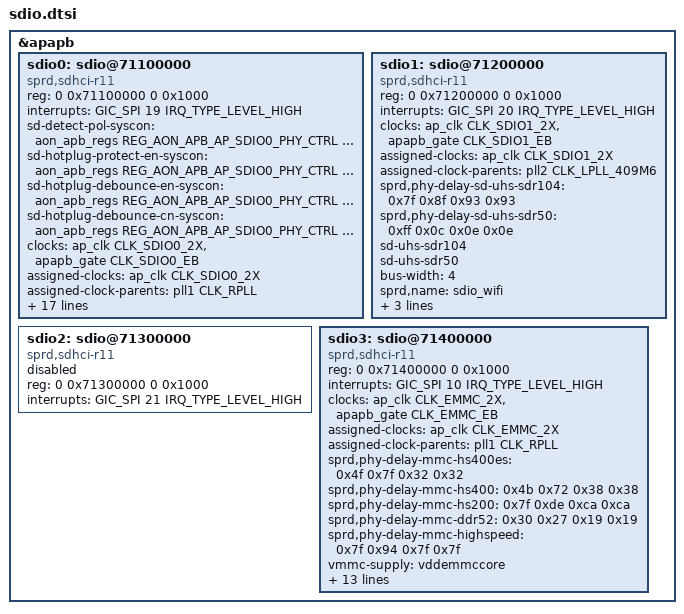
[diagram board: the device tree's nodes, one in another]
// SPDX-License-Identifier: GPL-2.0-only
/*
 * Unisoc UMS312 SDIO dts file
 *
 * Copyright (C) 2020~2021, Unisoc Communications Inc.
 */
&apapb {
	sdio0: sdio@71100000 {
		compatible = "sprd,sdhci-r11";
		reg = <0 0x71100000 0 0x1000>;
		interrupts = <GIC_SPI 19 IRQ_TYPE_LEVEL_HIGH>;
		sd-detect-pol-syscon = <&aon_apb_regs
			REG_AON_APB_AP_SDIO0_PHY_CTRL
			MASK_AON_APB_AP_SDIO0_CARD_PRESENT_32K>;
		sd-hotplug-protect-en-syscon = <&aon_apb_regs
			REG_AON_APB_AP_SDIO0_PHY_CTRL
			MASK_AON_APB_AP_SDIO0_CARD_PROTECT_32K>;
		sd-hotplug-debounce-en-syscon = <&aon_apb_regs
			REG_AON_APB_AP_SDIO0_PHY_CTRL
			MASK_AON_APB_AP_SDIO0_CARDDET_DBNC_EN_32K>;
		sd-hotplug-debounce-cn-syscon = <&aon_apb_regs
			REG_AON_APB_AP_SDIO0_PHY_CTRL
			MASK_AON_APB_AP_SDIO0_CARDDET_DBNC_THD_32K>;
		clock-names = "sdio","enable";
		clocks = <&ap_clk  CLK_SDIO0_2X>,
			<&apapb_gate CLK_SDIO0_EB>;
		assigned-clocks = <&ap_clk CLK_SDIO0_2X>;
		assigned-clock-parents = <&pll1 CLK_RPLL>;
		status = "disabled";
	};

	sdio1: sdio@71200000 {
		compatible = "sprd,sdhci-r11";
		reg = <0 0x71200000 0 0x1000>;
		interrupts = <GIC_SPI 20 IRQ_TYPE_LEVEL_HIGH>;
		clock-names = "sdio", "enable";
		clocks = <&ap_clk CLK_SDIO1_2X>,
			<&apapb_gate CLK_SDIO1_EB>;
		assigned-clocks = <&ap_clk CLK_SDIO1_2X>;
		assigned-clock-parents = <&pll2 CLK_LPLL_409M6>;
		status = "disabled";
	};

	sdio2: sdio@71300000 {
		compatible = "sprd,sdhci-r11";
		reg = <0 0x71300000 0 0x1000>;
		interrupts = <GIC_SPI 21 IRQ_TYPE_LEVEL_HIGH>;
		status = "disabled";
	};

	sdio3: sdio@71400000 {
		compatible = "sprd,sdhci-r11";
		reg = <0 0x71400000 0 0x1000>;
		interrupts = <GIC_SPI 10 IRQ_TYPE_LEVEL_HIGH>;
		clock-names = "sdio","enable";
		clocks = <&ap_clk CLK_EMMC_2X>,
			<&apapb_gate CLK_EMMC_EB>;
		assigned-clocks = <&ap_clk CLK_EMMC_2X>;
		assigned-clock-parents = <&pll1 CLK_RPLL>;
		status = "disabled";
	};
};

&sdio0 {
	sprd,phy-delay-sd-uhs-sdr104 = <0x86 0x6e 0x70 0x70>;
	sprd,phy-delay-sd-uhs-sdr50 = <0x7f 0x7f 0xf6 0xf6>;
	sprd,phy-delay-sd-highspeed = <0x0 0x24 0x24 0x24>;
	sprd,phy-delay-legacy = <0x0 0x24 0x24 0x24>;
	vmmc-supply = <&vddsdcore>;
	vqmmc-supply = <&vddsdio>;
	voltage-ranges = <3000 3000>;
	bus-width = <4>;
	sd-uhs-sdr104;
	sd-uhs-sdr50;
	sprd,name = "sdio_sd";
	sprd,sdio-adma;
	no-sdio;
	no-mmc;
	status = "okay";
};

&sdio1 {
	sprd,phy-delay-sd-uhs-sdr104 = <0x7f 0x8f 0x93 0x93>;
	sprd,phy-delay-sd-uhs-sdr50 = <0xff 0x0c 0x0e 0x0e>;
	sd-uhs-sdr104;
	sd-uhs-sdr50;
	bus-width = <4>;
	sprd,name = "sdio_wifi";
	sprd,sdio-adma;
	no-sd;
	no-mmc;
	status = "okay";
};

&sdio3 {
	sprd,phy-delay-mmc-hs400es = <0x4f 0x7f 0x32 0x32>;
	sprd,phy-delay-mmc-hs400 = <0x4b 0x72 0x38 0x38>;
	sprd,phy-delay-mmc-hs200 = <0x7f 0xde 0xca 0xca>;
	sprd,phy-delay-mmc-ddr52 = <0x30 0x27 0x19 0x19>;
	sprd,phy-delay-mmc-highspeed = <0x7f 0x94 0x7f 0x7f>;
	vmmc-supply = <&vddemmccore>;
	voltage-ranges = <3000 3000>;
	bus-width = <8>;
	non-removable;
	cap-mmc-hw-reset;
	mmc-hs400-enhanced-strobe;
	mmc-hs400-1_8v;
	mmc-hs200-1_8v;
	mmc-ddr-1_8v;
	sprd,name = "sdio_emmc";
	sprd,sdio-adma;
	no-sdio;
	no-sd;
	status = "okay";
	supports-swcq;
};
